# sam67_dmpac_wrap0_DMPAC_TOP_CFG_SLV_PAR_DOF_CFG_VP_MMR_VBUSP_DOFCORE register map
Vendor: Texas Instruments
Peripheral module from a debugger description file (folder J722S).
Registers are 32-bit, read-write, reset 0x0 unless marked. A register's access mark holds for its fields unless they carry their own. Offsets are as the file gives them; lines under a group give offsets from that group; [hi:lo] are bit positions; {n}, {i} and the like mark numbered series; 'fields as' and 'values as' point back to an identical list; <NAME> marks a mode.

## sam67_dmpac_wrap0_DMPAC_TOP_CFG_SLV_PAR_DOF_CFG_VP_MMR_VBUSP_DOFCORE
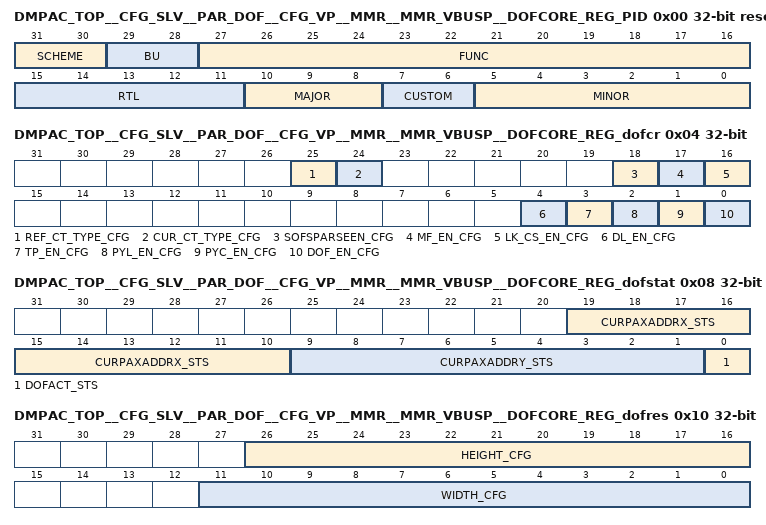
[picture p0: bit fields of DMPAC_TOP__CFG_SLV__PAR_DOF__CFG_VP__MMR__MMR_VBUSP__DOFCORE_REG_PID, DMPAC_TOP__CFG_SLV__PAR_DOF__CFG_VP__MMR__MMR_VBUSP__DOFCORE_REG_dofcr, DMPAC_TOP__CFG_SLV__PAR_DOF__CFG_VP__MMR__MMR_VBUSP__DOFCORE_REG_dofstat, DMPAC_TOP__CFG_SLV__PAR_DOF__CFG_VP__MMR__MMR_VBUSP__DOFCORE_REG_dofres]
0x00 DMPAC_TOP__CFG_SLV__PAR_DOF__CFG_VP__MMR__MMR_VBUSP__DOFCORE_REG_PID ro reset 0x64900100 — DOF PID
  [31:30] SCHEME — Used to distinguish between old scheme and new scheme. Spare bit to encode future schemes
  [29:28] BU — BU indicator DSPS ==> 0x0 WTBU ==> 0x1 Processors ==> 0x2
  [27:16] FUNC — Function indicates a software compatible module family. If there is no level of software compatibility a new FUNC number, and hence PID, should be assigned.
  [15:11] RTL — RTL Version. R as described in PDR with additional clarifications and definitions below. Must be easily ECO-able or controlled during fabrication. Ideally through a top level metal mask or e-fuse. This number is maintained/owned by IP design owner. RTL follows a numbering such as X.Y.R.Z which are explained in this table. R changes ONLY when: (1) PDS uploads occur which may have been due to spec changes (2) Bug fixes occur (3) Resets to '0' when X or Y changes. Design team has an internal 'Z' (customer invisible) number which increments on every drop that happens due to DV and RTL updates. Z resets to 0 when R increments.
  [10:8] MAJOR — Major Revision. X as described in PDR with additional clarifications/definitions below. This number is owned/maintained by IP specification owner. X is part of IP numbering X.Y.R.Z. X changes ONLY when: (1) There is a major feature addition. An example would be adding Master Mode to Utopia Level2. The Func field (or Class/Type in old PID format) will remain the same. X does NOT change due to: (1) Bug fixes (2) Change in feature parameters.
  [7:6] CUSTOM — Indicates a special version for a particular device. Consequence of use may avoid use of standard Chip Support Library (CSL) / Drivers. 0 if non-custom.
  [5:0] MINOR — Minor Revision. Y as described in PDR with additional clarifications/definitions below. This number is owned/maintained by IP specification owner. Y changes ONLY when: (1) Features are scaled (up or down). Flexibility exists in that this feature scalability may either be represented in the Y change or a specific register in the IP that indicates which features are exactly available. (2) When feature creeps from Is-Not list to Is list. But this may not be the case once it sees silicon - in which case X will change. Y does NOT change due to: (1) Bug fixes (2) Typos or clarifications (3) major functional/feature change/addition/deletion. Instead these changes may be reflected via R, S, X as applicable. Spec owner maintains a customer-invisible number 'S' which changes due to: (1) Typos/clarifications (2) Bug documentation. Note that this bug is not due to a spec change but due to implementation. Nevertheless, the spec tracks the IP bugs. An RTL release (say for silicon PG1.1) that occurs due to bug fix should document the corresponding spec number (X.Y.S) in its release notes.
0x04 DMPAC_TOP__CFG_SLV__PAR_DOF__CFG_VP__MMR__MMR_VBUSP__DOFCORE_REG_dofcr — Controls DOF operations
  [25] REF_CT_TYPE_CFG — Census transform type for reference image. 0: 24 bits generated for census transform by using a 5x5 neighborhood around the pixel. 1: 32 bits generated for census transform by using a 7x7 neighborhood around the pixel where only 8 pixels are used from the periphery.
  [24] CUR_CT_TYPE_CFG — Census transform type for current image. 0: 24 bits generated for census transform by using a 5x5 neighborhood around the pixel. 1: 32 bits generated for census transform by using a 7x7 neighborhood around the pixel where only 8 pixels are used from the periphery.
  [18] SOFSPARSEEN_CFG — sparse optical flow enable bit. Set to 0x1 to enable sparse optical flow processing.
  [17] MF_EN_CFG — Median filter enable bit. Set to 0x1 to enable median filter processing.
  [16] LK_CS_EN_CFG — LK refinement and confidence score generation enable bit. Set to 0x1 to enable LK and CS processing.
  [4] DL_EN_CFG — Delayed Left Predictor Enable bit. Set to 0x1 to enable use of delayed left predictor during the DOF processing.
  [3] TP_EN_CFG — Temporal Predictor Enable bit. Set to 0x1 to enable use of temporal predictor during the DOF processing.
  [2] PYL_EN_CFG — Pyramidal Top Left Predictor Enable bit. Set to 0x1 to enable use of pyramidal top left predictor during DOF processing.
  [1] PYC_EN_CFG — Pyramidal Top Co-located Predictor Enable bit. Set to 0x1 to enable use of pyramidal top colocated predictor during DOF processing.
  [0] DOF_EN_CFG — DOF Enable. Set to 0x1 to enable DOF engine.
0x08 DMPAC_TOP__CFG_SLV__PAR_DOF__CFG_VP__MMR__MMR_VBUSP__DOFCORE_REG_dofstat ro — Provides status info
  [19:10] CURPAXADDRX_STS — Current Paxel Address X co-ordinate. Provides address of 2x2 paxel currently being processed.
  [9:1] CURPAXADDRY_STS — Current Paxel Address Y co-ordinate. Provides address of 2x2 paxel currently being processed.
  [0] DOFACT_STS — DOF Active Status. When read as 0x1, indicates DOF engine is in active state processing flow vector for the frame.
0x10 DMPAC_TOP__CFG_SLV__PAR_DOF__CFG_VP__MMR__MMR_VBUSP__DOFCORE_REG_dofres — Set up frame width, height
  [26:16] HEIGHT_CFG — Height of frame (in pixel) to be processed by Optical Flow engine. 1024 pixel max and 16 pixels min. Refer to algorithm parameter section for restrictions.
  [11:0] WIDTH_CFG — Width of frame (in pixel) to be processed by Optical Flow engine. 2048 pixel max and 32 pixels min. Refer to algorithm parameter section for restrictions.
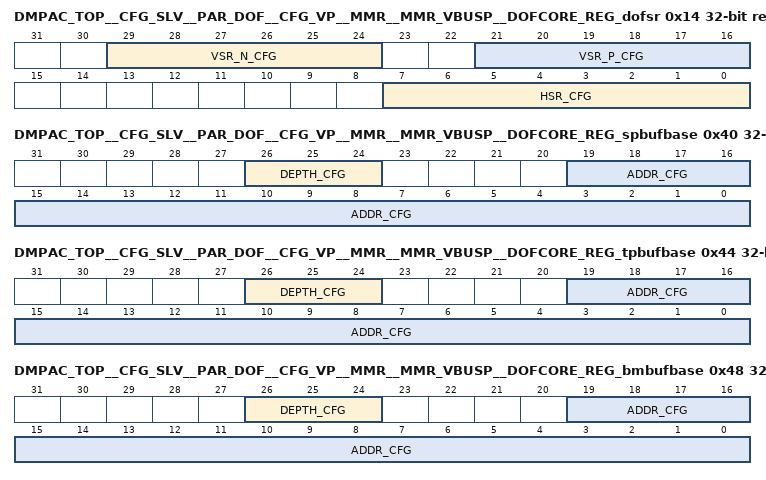
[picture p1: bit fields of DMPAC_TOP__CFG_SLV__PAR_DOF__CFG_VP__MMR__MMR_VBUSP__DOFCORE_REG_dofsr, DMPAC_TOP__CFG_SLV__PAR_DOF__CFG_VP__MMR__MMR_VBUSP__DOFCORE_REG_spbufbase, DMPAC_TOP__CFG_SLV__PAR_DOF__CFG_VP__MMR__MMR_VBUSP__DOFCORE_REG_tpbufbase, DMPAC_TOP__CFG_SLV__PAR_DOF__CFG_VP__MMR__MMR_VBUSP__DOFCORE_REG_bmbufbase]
0x14 DMPAC_TOP__CFG_SLV__PAR_DOF__CFG_VP__MMR__MMR_VBUSP__DOFCORE_REG_dofsr reset 0x303000BF — Setup horizontal and vertical search range.
  [29:24] VSR_N_CFG — Negative or Upward direction Vertical Search Range in pixels.
  [21:16] VSR_P_CFG — Positive or Downward direction Vertical Search Range in pixels.
  [7:0] HSR_CFG — Horizontal Search Range in pixels in both the directions.
0x18 DMPAC_TOP__CFG_SLV__PAR_DOF__CFG_VP__MMR__MMR_VBUSP__DOFCORE_REG_sof — Controls sparse optical flow output processing
  [11:0] MAX_OUTPUT_COUNT_PER_LINE_CFG — Maximum number of MV output per line in case of sparse optical flow processing
0x20 DMPAC_TOP__CFG_SLV__PAR_DOF__CFG_VP__MMR__MMR_VBUSP__DOFCORE_REG_cfgwbase — Current Frame GW Base address in SL2
  [19:0] ADDR_CFG — SL2 base byte address. Should be aligned to 64 bytes
0x24 DMPAC_TOP__CFG_SLV__PAR_DOF__CFG_VP__MMR__MMR_VBUSP__DOFCORE_REG_cfgwwidth — CFGW width, Max 2048 pix
  [12:0] WIDTH_CFG — Width of Frame Growing Window in bytes. Should be multiple of 64 bytes
0x28 DMPAC_TOP__CFG_SLV__PAR_DOF__CFG_VP__MMR__MMR_VBUSP__DOFCORE_REG_cfgwheight — CFGW Height, Max 32 rows
  [4:0] HEIGHT_CFG — Height of Frame Growing Window. Max 31 rows.
0x30 DMPAC_TOP__CFG_SLV__PAR_DOF__CFG_VP__MMR__MMR_VBUSP__DOFCORE_REG_rfgwbase — Reference Frame GW Base address in SL2
  fields as DMPAC_TOP__CFG_SLV__PAR_DOF__CFG_VP__MMR__MMR_VBUSP__DOFCORE_REG_cfgwbase
0x34 DMPAC_TOP__CFG_SLV__PAR_DOF__CFG_VP__MMR__MMR_VBUSP__DOFCORE_REG_rfgwwidth — RFGW width, Max 2048 pix
  fields as DMPAC_TOP__CFG_SLV__PAR_DOF__CFG_VP__MMR__MMR_VBUSP__DOFCORE_REG_cfgwwidth
0x38 DMPAC_TOP__CFG_SLV__PAR_DOF__CFG_VP__MMR__MMR_VBUSP__DOFCORE_REG_rfgwheight — RFGW height, Max 256 rows
  [7:0] HEIGHT_CFG — Height of Frame Growing Window. Max 255 rows.
0x40 DMPAC_TOP__CFG_SLV__PAR_DOF__CFG_VP__MMR__MMR_VBUSP__DOFCORE_REG_spbufbase reset 0x2000000 — Base address in SL2
  [26:24] DEPTH_CFG — Depth of SL2 buffer
  [19:0] ADDR_CFG — SL2 base byte address. Should be aligned to 64 bytes
0x44 DMPAC_TOP__CFG_SLV__PAR_DOF__CFG_VP__MMR__MMR_VBUSP__DOFCORE_REG_tpbufbase reset 0x2000000 — Base address in SL2
  fields as DMPAC_TOP__CFG_SLV__PAR_DOF__CFG_VP__MMR__MMR_VBUSP__DOFCORE_REG_spbufbase
0x48 DMPAC_TOP__CFG_SLV__PAR_DOF__CFG_VP__MMR__MMR_VBUSP__DOFCORE_REG_bmbufbase reset 0x2000000 — Base address in SL2
  fields as DMPAC_TOP__CFG_SLV__PAR_DOF__CFG_VP__MMR__MMR_VBUSP__DOFCORE_REG_spbufbase
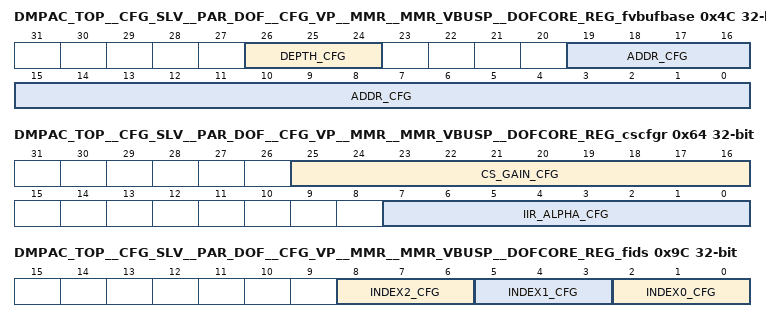
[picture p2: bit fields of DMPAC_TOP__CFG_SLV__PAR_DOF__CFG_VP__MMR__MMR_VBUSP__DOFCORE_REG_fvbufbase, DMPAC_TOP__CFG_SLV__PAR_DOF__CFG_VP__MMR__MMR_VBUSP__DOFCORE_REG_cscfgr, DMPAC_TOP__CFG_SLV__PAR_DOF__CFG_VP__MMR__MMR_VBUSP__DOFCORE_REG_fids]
0x4C DMPAC_TOP__CFG_SLV__PAR_DOF__CFG_VP__MMR__MMR_VBUSP__DOFCORE_REG_fvbufbase reset 0x2000000 — Base address in SL2
  fields as DMPAC_TOP__CFG_SLV__PAR_DOF__CFG_VP__MMR__MMR_VBUSP__DOFCORE_REG_spbufbase
0x60 DMPAC_TOP__CFG_SLV__PAR_DOF__CFG_VP__MMR__MMR_VBUSP__DOFCORE_REG_msfr reset 0x18 — 5b unsigned integer for Step Search cost function
  [4:0] MSF_CFG — Motion smoothness factor
0x64 DMPAC_TOP__CFG_SLV__PAR_DOF__CFG_VP__MMR__MMR_VBUSP__DOFCORE_REG_cscfgr — Feature filter parameters, confidence score scaling factor setup
  [25:16] CS_GAIN_CFG — Multiplier factor (Gain) for the combined confidence score. The sum of individual scores from different decision trees are multiplied by CS Gain before scaling to final 4bit (16 levels) confidence score value.
  [7:0] IIR_ALPHA_CFG — Coefficient for IIR filter used for smoothing horizontal flow vector gradient. The usage can be illustrated as: SmoothU(i,j)= [ U(i,j)*alpha + SmoothU(i-1,j)*beta + round ]>>8 where beta = 256-alpha round = 128
0x70 DMPAC_TOP__CFG_SLV__PAR_DOF__CFG_VP__MMR__MMR_VBUSP__DOFCORE_REG_psa_ctrl — Control register for calculating 32b CRC signature on flow vector output
  [0] PSA_EN_CFG — Enable calculating 32b CRC signature on 32b flow vector and confidence score output
0x74 DMPAC_TOP__CFG_SLV__PAR_DOF__CFG_VP__MMR__MMR_VBUSP__DOFCORE_REG_psa_signature ro reset 0xFFFFFFFF — 32b CRC signature calculated on flow vector output
  [31:0] CRC_STS — 32b CRC signature value as calculated on 32b flow vector and confidence score output
0x80 DMPAC_TOP__CFG_SLV__PAR_DOF__CFG_VP__MMR__MMR_VBUSP__DOFCORE_REG_th0 — Confidence Score Decision Tree[a] Threshold 0. First Branch. There are a total of 16 trees and each tree has 8 programed CFG parameters. Each tree is essentially a 4-1 selector MUX outputs one of 4 MMR configured weights. After all 16 trees are evaluated; the 16 winning weights are summed giving the final Confidence Score.
  [15:0] THRESHOLD_CFG — Threshold 0 value. If Feature(Index0).ge.Thresh0 then 2ndBranch11 else 2ndBranch10
0x84 DMPAC_TOP__CFG_SLV__PAR_DOF__CFG_VP__MMR__MMR_VBUSP__DOFCORE_REG_th10 — Confidence Score Decision Tree[a] Threshold 10. 2nd Branch, only evaluated if failing 1st Branch
  [15:0] THRESHOLD_CFG — Threshold 10 value. If Feature(Index10).ge.Thresh10 then Weight01 else Weight00
0x88 DMPAC_TOP__CFG_SLV__PAR_DOF__CFG_VP__MMR__MMR_VBUSP__DOFCORE_REG_th11 — Confidence Score Decision Tree[a] Threshold 11. 2nd Branch, only evaluated if passing 1st Branch
  [15:0] THRESHOLD_CFG — Threshold 11 value. If Feature(Index11).ge.Thresh11 then Weight11 else Weight10
0x8C DMPAC_TOP__CFG_SLV__PAR_DOF__CFG_VP__MMR__MMR_VBUSP__DOFCORE_REG_wt00 — Confidence Score Decision Tree[a] Weight 00
  [15:0] WEIGHT_CFG — Weight 00 value for Confidence Score Decision Tree
0x90 DMPAC_TOP__CFG_SLV__PAR_DOF__CFG_VP__MMR__MMR_VBUSP__DOFCORE_REG_wt01 — Confidence Score Decision Tree[a] Weight 01
  [15:0] WEIGHT_CFG — Weight 01 value for Confidence Score Decision Tree
0x94 DMPAC_TOP__CFG_SLV__PAR_DOF__CFG_VP__MMR__MMR_VBUSP__DOFCORE_REG_wt10 — Confidence Score Decision Tree Tree[a] Weight 10
  [15:0] WEIGHT_CFG — Weight 10 value for Confidence Score Decision Tree
0x98 DMPAC_TOP__CFG_SLV__PAR_DOF__CFG_VP__MMR__MMR_VBUSP__DOFCORE_REG_wt11 — Confidence Score Decision Tree[a] Weight 11
  [15:0] WEIGHT_CFG — Weight 11 value for Confidence Score Decision Tree
0x9C DMPAC_TOP__CFG_SLV__PAR_DOF__CFG_VP__MMR__MMR_VBUSP__DOFCORE_REG_fids — Decision Tree n=0-to-15 Feature Indices. Selects one of 8 data values to compare. 0:Winner Cost 1:Texture 2:Flow Grad U 3:Flow Grad V 4:Aggregated Winner Cost 5:Aggregated Texture 6:Aggregated Flow Grad U 7:Aggregated Flow Grad V
  [8:6] INDEX2_CFG — Specifies the index of a feature (in the confidence score feature vector) to be used as the 3rd feature in the decision tree traversal 0: Winner Cost 1: Texture 2: Flow Grad U 3: Flow Grad V 4: Aggregated Winner Cost 5: Aggregated Texture 6: Aggregated Flow Grad U 7: Aggregated Flow Grad V
  [5:3] INDEX1_CFG — Specifies the index of a feature (in the confidence score feature vector) to be used as the 2nd feature in the decision tree traversal 0: Winner Cost 1: Texture 2: Flow Grad U 3: Flow Grad V 4: Aggregated Winner Cost 5: Aggregated Texture 6: Aggregated Flow Grad U 7: Aggregated Flow Grad V
  [2:0] INDEX0_CFG — Specifies the index of a feature (in the confidence score feature vector) to be used as the 1st feature in the decision tree traversal 0: Winner Cost 1: Texture 2: Flow Grad U 3: Flow Grad V 4: Aggregated Winner Cost 5: Aggregated Texture 6: Aggregated Flow Grad U 7: Aggregated Flow Grad V
0x300 DMPAC_TOP__CFG_SLV__PAR_DOF__CFG_VP__MMR__MMR_VBUSP__DOFCORE_REG_dofcshist ro — Confidence Score Histogram Number of pixels having confidence score value of Bin Index
  [23:0] BIN_STS — Number of pixels having confidence score value of Bin Index
